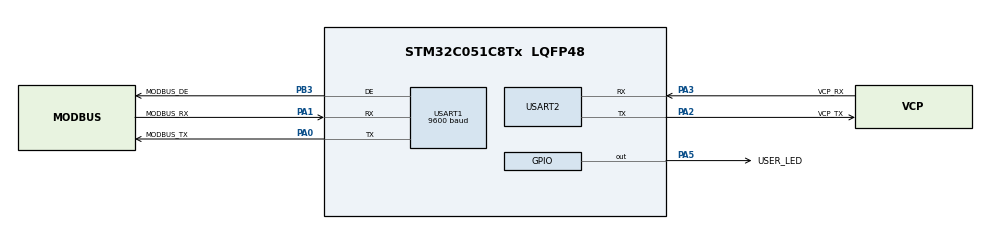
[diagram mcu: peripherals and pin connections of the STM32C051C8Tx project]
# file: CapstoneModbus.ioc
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Mcu.Family=STM32C0
Mcu.Name=STM32C051C8Tx
Mcu.Package=LQFP48
NVIC.TIM2_IRQn=true\:0\:0\:false\:false\:true\:true\:false\:true
NVIC.USART1_IRQn=true\:0\:0\:false\:false\:true\:true\:false\:true
NVIC.USART2_IRQn=true\:0\:0\:false\:false\:true\:true\:false\:true
PA0.GPIO_Label=MODBUS_TX
PA0.Mode=Asynchronous
PA0.Signal=USART1_TX
PA1.GPIO_Label=MODBUS_RX
PA1.Mode=Asynchronous
PA1.Signal=USART1_RX
PA2.GPIO_Label=VCP_TX
PA2.Mode=Asynchronous
PA2.Signal=USART2_TX
PA3.GPIO_Label=VCP_RX
PA3.Mode=Asynchronous
PA3.Signal=USART2_RX
PA5.GPIO_Label=USER_LED
PA5.PinState=GPIO_PIN_RESET
PA5.Signal=GPIO_Output
PB3.GPIO_Label=MODBUS_DE
PB3.Mode=Hardware Flow Control (RS485)
PB3.Signal=USART1_DE
ProjectManager.HeapSize=0x200
ProjectManager.StackSize=0x400
ProjectManager.TargetToolchain=STM32CubeIDE
RCC.ADCFreq_Value=48000000
RCC.AHBFreq_Value=48000000
RCC.CortexFreq_Value=48000000
RCC.DATA_CACHE_ENABLE=0
RCC.EXTERNAL_CLOCK_VALUE=12288000
RCC.HCLKFreq_Value=48000000
RCC.HSE_VALUE=8000000
RCC.HSISYSCLKDivider=RCC_HSI_DIV1
RCC.HSI_VALUE=48000000
RCC.INSTRUCTION_CACHE_ENABLE=0
RCC.LSE_VALUE=32768
RCC.SYSCLKFreq_VALUE=48000000
TIM2.Channel-Output\ Compare1\ No\ Output=TIM_CHANNEL_1
TIM2.Channel-Output\ Compare2\ No\ Output=TIM_CHANNEL_2
USART1.BaudRate=9600
USART1.VirtualMode-Asynchronous=VM_ASYNC
USART1.VirtualMode-Hardware\ Flow\ Control\ (RS485)=VM_ASYNC
USART2.VirtualMode-Asynchronous=VM_ASYNC
VP_TIM2_VS_ClockSourceINT.Mode=Internal
VP_TIM2_VS_OPM.Mode=OPM_bit
VP_TIM2_VS_no_output1.Mode=Output Compare1 No Output
VP_TIM2_VS_no_output2.Mode=Output Compare2 No Output
board=NUCLEO-C051C8

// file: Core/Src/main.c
/* USER CODE BEGIN Header */
/**
  ******************************************************************************
  * @file           : main.c
  * @brief          : Main program body
  ******************************************************************************
  * @attention
  *
  * Copyright (c) 2025 STMicroelectronics.
  * All rights reserved.
  *
  * This software is licensed under terms that can be found in the LICENSE file
  * in the root directory of this software component.
  * If no LICENSE file comes with this software, it is provided AS-IS.
  *
  ******************************************************************************
  */
/* USER CODE END Header */
#include "main.h"

TIM_HandleTypeDef htim2;

UART_HandleTypeDef huart1;
UART_HandleTypeDef huart2;

void SystemClock_Config(void);
static void MX_GPIO_Init(void);
static void MX_USART2_UART_Init(void);
static void MX_USART1_UART_Init(void);
static void MX_TIM2_Init(void);

int main(void)
{

  /* MCU Configuration--------------------------------------------------------*/

  /* Reset of all peripherals, Initializes the Flash interface and the Systick. */
  HAL_Init();

  /* Configure the system clock */
  SystemClock_Config();

  /* Initialize all configured peripherals */
  MX_GPIO_Init();
  MX_USART2_UART_Init();
  MX_USART1_UART_Init();
  MX_TIM2_Init();
  /* USER CODE BEGIN 2 */
  debug_init(&huart2);
  modbus_io_init(&huart1, HAL_RCC_GetPCLK1Freq(), &htim2, HAL_RCC_GetPCLK1Freq());
  modbus_controller_init(0x42);
  /* USER CODE END 2 */

  /* Infinite loop */
  while (1)
  {

    /* USER CODE BEGIN 3 */
	  modbus_controller_tick();
  }
  /* USER CODE END 3 */
}

void SystemClock_Config(void)
{
  RCC_OscInitTypeDef RCC_OscInitStruct = {0};
  RCC_ClkInitTypeDef RCC_ClkInitStruct = {0};

  __HAL_FLASH_SET_LATENCY(FLASH_LATENCY_1);

  /** Initializes the RCC Oscillators according to the specified parameters
  * in the RCC_OscInitTypeDef structure.
  */
  RCC_OscInitStruct.OscillatorType = RCC_OSCILLATORTYPE_HSI;
  RCC_OscInitStruct.HSIState = RCC_HSI_ON;
  RCC_OscInitStruct.HSIDiv = RCC_HSI_DIV1;
  RCC_OscInitStruct.HSICalibrationValue = RCC_HSICALIBRATION_DEFAULT;
  if (HAL_RCC_OscConfig(&RCC_OscInitStruct) != HAL_OK)
  {
    Error_Handler();
  }

  /** Initializes the CPU, AHB and APB buses clocks
  */
  RCC_ClkInitStruct.ClockType = RCC_CLOCKTYPE_HCLK|RCC_CLOCKTYPE_SYSCLK
                              |RCC_CLOCKTYPE_PCLK1;
  RCC_ClkInitStruct.SYSCLKSource = RCC_SYSCLKSOURCE_HSI;
  RCC_ClkInitStruct.SYSCLKDivider = RCC_SYSCLK_DIV1;
  RCC_ClkInitStruct.AHBCLKDivider = RCC_HCLK_DIV1;
  RCC_ClkInitStruct.APB1CLKDivider = RCC_APB1_DIV1;

  if (HAL_RCC_ClockConfig(&RCC_ClkInitStruct, FLASH_LATENCY_1) != HAL_OK)
  {
    Error_Handler();
  }
}

static void MX_TIM2_Init(void)
{

  TIM_ClockConfigTypeDef sClockSourceConfig = {0};
  TIM_MasterConfigTypeDef sMasterConfig = {0};
  TIM_OC_InitTypeDef sConfigOC = {0};

  htim2.Instance = TIM2;
  htim2.Init.Prescaler = 0;
  htim2.Init.CounterMode = TIM_COUNTERMODE_UP;
  htim2.Init.Period = 4294967295;
  htim2.Init.ClockDivision = TIM_CLOCKDIVISION_DIV1;
  htim2.Init.AutoReloadPreload = TIM_AUTORELOAD_PRELOAD_DISABLE;
  if (HAL_TIM_Base_Init(&htim2) != HAL_OK)
  {
    Error_Handler();
  }
  sClockSourceConfig.ClockSource = TIM_CLOCKSOURCE_INTERNAL;
  if (HAL_TIM_ConfigClockSource(&htim2, &sClockSourceConfig) != HAL_OK)
  {
    Error_Handler();
  }
  if (HAL_TIM_OC_Init(&htim2) != HAL_OK)
  {
    Error_Handler();
  }
  if (HAL_TIM_OnePulse_Init(&htim2, TIM_OPMODE_SINGLE) != HAL_OK)
  {
    Error_Handler();
  }
  sMasterConfig.MasterOutputTrigger = TIM_TRGO_RESET;
  sMasterConfig.MasterSlaveMode = TIM_MASTERSLAVEMODE_DISABLE;
  if (HAL_TIMEx_MasterConfigSynchronization(&htim2, &sMasterConfig) != HAL_OK)
  {
    Error_Handler();
  }
  sConfigOC.OCMode = TIM_OCMODE_TIMING;
  sConfigOC.Pulse = 0;
  sConfigOC.OCPolarity = TIM_OCPOLARITY_HIGH;
  sConfigOC.OCFastMode = TIM_OCFAST_DISABLE;
  if (HAL_TIM_OC_ConfigChannel(&htim2, &sConfigOC, TIM_CHANNEL_1) != HAL_OK)
  {
    Error_Handler();
  }
  if (HAL_TIM_OC_ConfigChannel(&htim2, &sConfigOC, TIM_CHANNEL_2) != HAL_OK)
  {
    Error_Handler();
  }

}

static void MX_USART1_UART_Init(void)
{

  huart1.Instance = USART1;
  huart1.Init.BaudRate = 9600;
  huart1.Init.WordLength = UART_WORDLENGTH_8B;
  huart1.Init.StopBits = UART_STOPBITS_1;
  huart1.Init.Parity = UART_PARITY_NONE;
  huart1.Init.Mode = UART_MODE_TX_RX;
  huart1.Init.HwFlowCtl = UART_HWCONTROL_NONE;
  huart1.Init.OverSampling = UART_OVERSAMPLING_16;
  huart1.Init.OneBitSampling = UART_ONE_BIT_SAMPLE_DISABLE;
  huart1.Init.ClockPrescaler = UART_PRESCALER_DIV1;
  huart1.AdvancedInit.AdvFeatureInit = UART_ADVFEATURE_NO_INIT;
  if (HAL_RS485Ex_Init(&huart1, UART_DE_POLARITY_HIGH, 0, 0) != HAL_OK)
  {
    Error_Handler();
  }
  if (HAL_UARTEx_SetTxFifoThreshold(&huart1, UART_TXFIFO_THRESHOLD_1_8) != HAL_OK)
  {
    Error_Handler();
  }
  if (HAL_UARTEx_SetRxFifoThreshold(&huart1, UART_RXFIFO_THRESHOLD_1_8) != HAL_OK)
  {
    Error_Handler();
  }
  if (HAL_UARTEx_DisableFifoMode(&huart1) != HAL_OK)
  {
    Error_Handler();
  }

}

static void MX_USART2_UART_Init(void)
{

  huart2.Instance = USART2;
  huart2.Init.BaudRate = 115200;
  huart2.Init.WordLength = UART_WORDLENGTH_8B;
  huart2.Init.StopBits = UART_STOPBITS_1;
  huart2.Init.Parity = UART_PARITY_NONE;
  huart2.Init.Mode = UART_MODE_TX_RX;
  huart2.Init.HwFlowCtl = UART_HWCONTROL_NONE;
  huart2.Init.OverSampling = UART_OVERSAMPLING_16;
  huart2.Init.OneBitSampling = UART_ONE_BIT_SAMPLE_DISABLE;
  huart2.Init.ClockPrescaler = UART_PRESCALER_DIV1;
  huart2.AdvancedInit.AdvFeatureInit = UART_ADVFEATURE_NO_INIT;
  if (HAL_UART_Init(&huart2) != HAL_OK)
  {
    Error_Handler();
  }
  if (HAL_UARTEx_SetTxFifoThreshold(&huart2, UART_TXFIFO_THRESHOLD_1_8) != HAL_OK)
  {
    Error_Handler();
  }
  if (HAL_UARTEx_SetRxFifoThreshold(&huart2, UART_RXFIFO_THRESHOLD_1_8) != HAL_OK)
  {
    Error_Handler();
  }
  if (HAL_UARTEx_DisableFifoMode(&huart2) != HAL_OK)
  {
    Error_Handler();
  }

}

static void MX_GPIO_Init(void)
{
  GPIO_InitTypeDef GPIO_InitStruct = {0};

  /* GPIO Ports Clock Enable */
  __HAL_RCC_GPIOA_CLK_ENABLE();
  __HAL_RCC_GPIOB_CLK_ENABLE();

  /*Configure GPIO pin Output Level */
  HAL_GPIO_WritePin(USER_LED_GPIO_Port, USER_LED_Pin, GPIO_PIN_RESET);

  /*Configure GPIO pin : USER_LED_Pin */
  GPIO_InitStruct.Pin = USER_LED_Pin;
  GPIO_InitStruct.Mode = GPIO_MODE_OUTPUT_PP;
  GPIO_InitStruct.Pull = GPIO_NOPULL;
  GPIO_InitStruct.Speed = GPIO_SPEED_FREQ_LOW;
  HAL_GPIO_Init(USER_LED_GPIO_Port, &GPIO_InitStruct);

}

void Error_Handler(void)
{
  __disable_irq();
  while (1)
  {
  }
}
